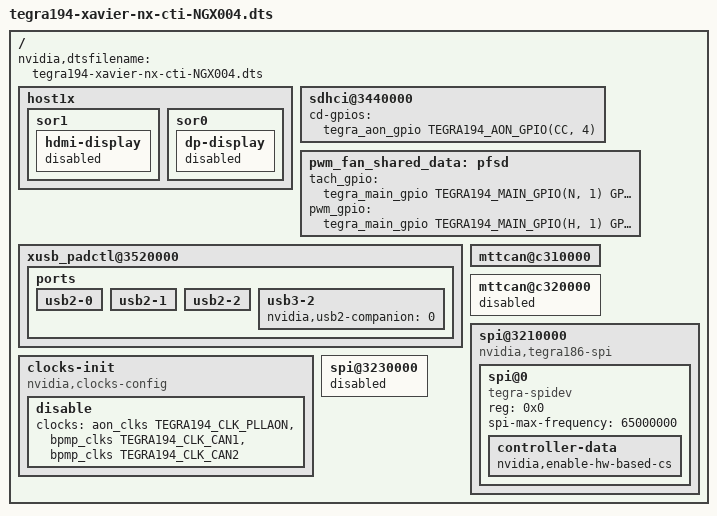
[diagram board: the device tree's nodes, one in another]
#include "tegra194-xavier-nx-cti-base.dtsi"
#include "common/tegra194-nx-cti-NGX014-USBC.dtsi"
/{

	nvidia,dtsfilename = "tegra194-xavier-nx-cti-NGX004.dts";

	host1x {
		sor1 {
			hdmi-display {
				status = "disabled";
			};
		};
		sor0 {
			dp-display {
				status = "disabled";
			};
		};
	};
    
	sdhci@3440000 {
        cd-gpios = <&tegra_aon_gpio TEGRA194_AON_GPIO(CC, 4) 0>;

    };

   pwm_fan_shared_data: pfsd
   {
        tach_gpio = <&tegra_main_gpio TEGRA194_MAIN_GPIO(N, 1) GPIO_ACTIVE_LOW>;
        pwm_gpio = <&tegra_main_gpio TEGRA194_MAIN_GPIO(H, 1) GPIO_ACTIVE_LOW>;
   };

    xusb_padctl@3520000 {
        ports {
            usb2-0 {
                status = "okay";
            };
            usb2-1 {
                status = "okay";
            };
            usb2-2 {
                status = "okay";
            };
            usb3-2 {
                nvidia,usb2-companion = <0>;
                status = "okay";
            };
        };
    };
	
	clocks-init {
		compatible = "nvidia,clocks-config";
		status = "okay";
		disable {
			clocks = <&aon_clks TEGRA194_CLK_PLLAON>,
				<&bpmp_clks TEGRA194_CLK_CAN1>,
				<&bpmp_clks TEGRA194_CLK_CAN2>;
		};
	};

    mttcan@c310000 {
        status = "okay";
    };

    mttcan@c320000 {
        status = "disabled";
    };
    
 
    spi@3210000{/*SPI1*/
		status = "okay";
		compatible = "nvidia,tegra186-spi";
		spi@0 {
			compatible = "tegra-spidev";
			reg = <0x0>;
			spi-max-frequency = <65000000>;
				controller-data{
				nvidia,enable-hw-based-cs;
			};
		};
	};

	
	spi@3230000{
		status = "disabled";
	};



};
